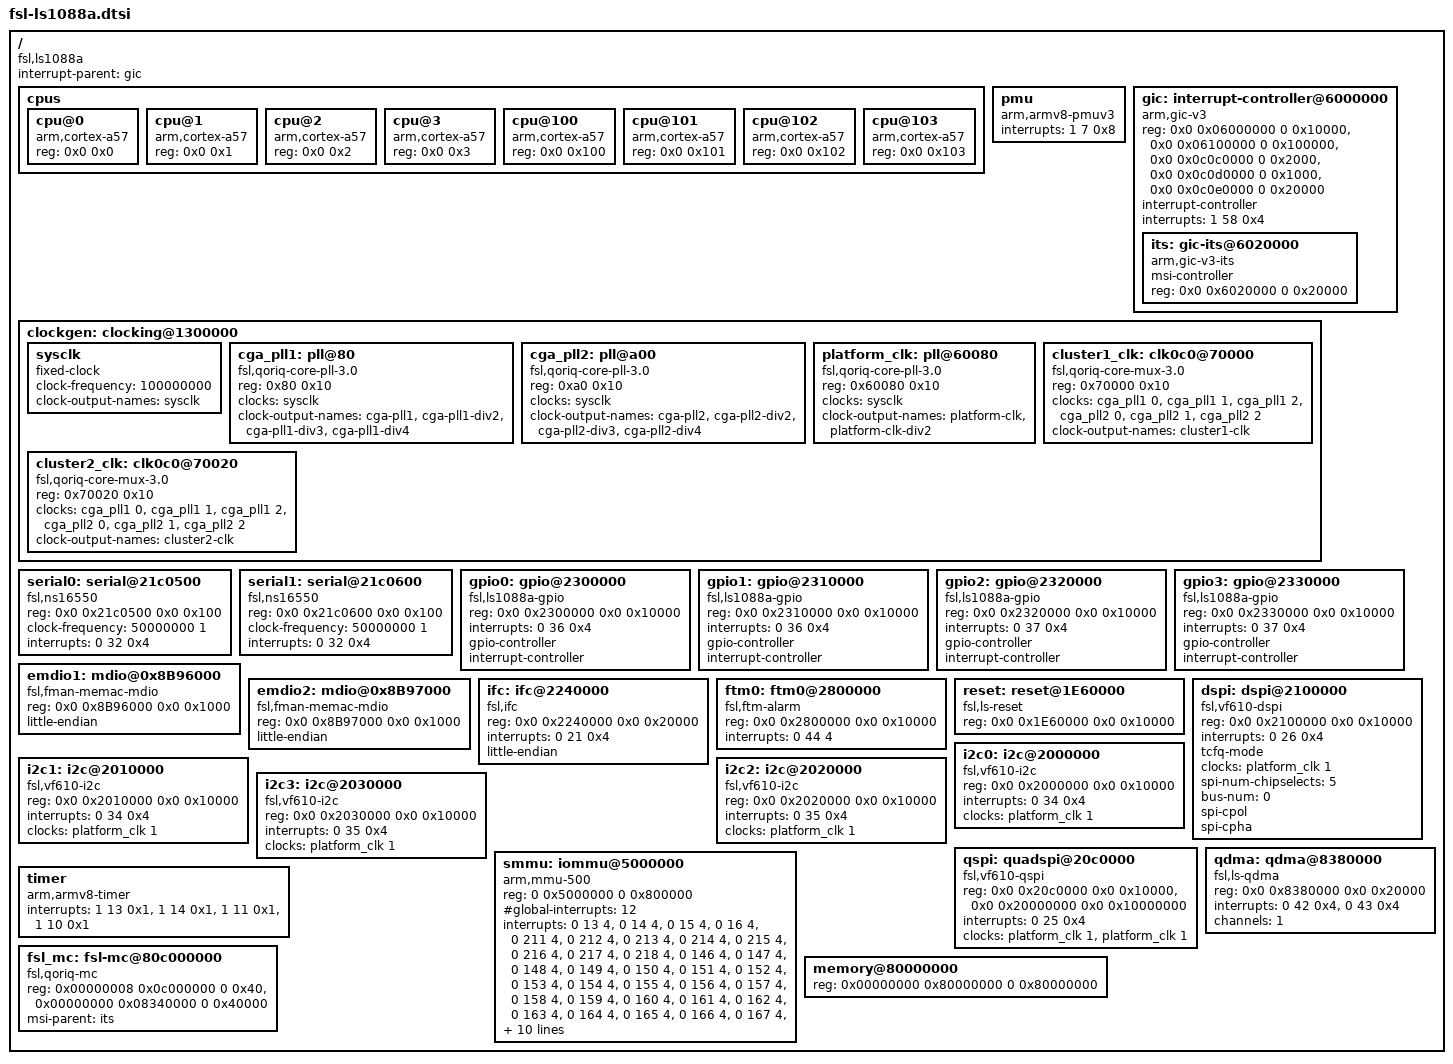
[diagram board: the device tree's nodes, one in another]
/*
 * Device Tree Include file for Freescale Layerscape-1088A family SoC.
 *
 * Copyright (C) 2015, Freescale Semiconductor
 *
 */

/memreserve/ 0x80000000 0x00010000;

/ {
	compatible = "fsl,ls1088a";
	interrupt-parent = <&gic>;
	#address-cells = <2>;
	#size-cells = <2>;

	cpus {
		#address-cells = <2>;
		#size-cells = <0>;

		/* We have 2 clusters having 4 Cortex-A57 cores each */
		cpu@0 {
			device_type = "cpu";
			compatible = "arm,cortex-a57";
			reg = <0x0 0x0>;
		};

		cpu@1 {
			device_type = "cpu";
			compatible = "arm,cortex-a57";
			reg = <0x0 0x1>;
		};

		cpu@2 {
			device_type = "cpu";
			compatible = "arm,cortex-a57";
			reg = <0x0 0x2>;
		};

		cpu@3 {
			device_type = "cpu";
			compatible = "arm,cortex-a57";
			reg = <0x0 0x3>;
		};

		cpu@100 {
			device_type = "cpu";
			compatible = "arm,cortex-a57";
			reg = <0x0 0x100>;
		};

		cpu@101 {
			device_type = "cpu";
			compatible = "arm,cortex-a57";
			reg = <0x0 0x101>;
		};

		cpu@102 {
			device_type = "cpu";
			compatible = "arm,cortex-a57";
			reg = <0x0 0x102>;
		};

		cpu@103 {
			device_type = "cpu";
			compatible = "arm,cortex-a57";
			reg = <0x0 0x103>;
		};
	};

	pmu {
		compatible = "arm,armv8-pmuv3";
		interrupts = <1 7 0x8>; /* PMU PPI, Level low type */
	};

	gic: interrupt-controller@6000000 {
		compatible = "arm,gic-v3";
		reg = <0x0 0x06000000 0 0x10000>, /* GIC Dist */
		      <0x0 0x06100000 0 0x100000>, /* GICR(RD_base+SGI_base)*/
		      <0x0 0x0c0c0000 0 0x2000>, /* GICC */
		      <0x0 0x0c0d0000 0 0x1000>, /* GICH */
		      <0x0 0x0c0e0000 0 0x20000>; /* GICV */
		#interrupt-cells = <3>;
		#address-cells = <2>;
		#size-cells = <2>;
		ranges;
		interrupt-controller;
		interrupts = <1 58 0x4>;

		its: gic-its@6020000 {
			compatible = "arm,gic-v3-its";
			msi-controller;
			reg = <0x0 0x6020000 0 0x20000>;
		};
	};

	clockgen: clocking@1300000 {
		#address-cells = <1>;
		#size-cells = <1>;
		ranges = <0x0 0x0 0x1300000 0xa0000>;

		sysclk: sysclk {
			compatible = "fixed-clock";
			#clock-cells = <0>;
			clock-frequency = <100000000>;
			clock-output-names = "sysclk";
		};

		cga_pll1: pll@80 {
			compatible = "fsl,qoriq-core-pll-3.0";
			#clock-cells = <1>;
			reg = <0x80 0x10>;
			clocks = <&sysclk>;
			clock-output-names = "cga-pll1", "cga-pll1-div2",
					     "cga-pll1-div3", "cga-pll1-div4";
		};

		cga_pll2: pll@a00 {
			compatible = "fsl,qoriq-core-pll-3.0";
			#clock-cells = <1>;
			reg = <0xa0 0x10>;
			clocks = <&sysclk>;
			clock-output-names = "cga-pll2", "cga-pll2-div2",
					     "cga-pll2-div3", "cga-pll2-div4";
		};


		platform_clk: pll@60080 {
			compatible = "fsl,qoriq-core-pll-3.0";
			#clock-cells = <1>;
			reg = <0x60080 0x10>;
			clocks = <&sysclk>;
			clock-output-names = "platform-clk",
					     "platform-clk-div2";
		};

		cluster1_clk: clk0c0@70000 {
			compatible = "fsl,qoriq-core-mux-3.0";
			#clock-cells = <0>;
			reg = <0x70000 0x10>;
			clock-names = "pll1cga", "pll1cga-div2", "pll1cga-div4",
				      "pll2cga", "pll2cga-div2", "pll2cga-div4";
			clocks = <&cga_pll1 0>, <&cga_pll1 1>, <&cga_pll1 2>,
				 <&cga_pll2 0>, <&cga_pll2 1>, <&cga_pll2 2>;
			clock-output-names = "cluster1-clk";
		};

		cluster2_clk: clk0c0@70020 {
			compatible = "fsl,qoriq-core-mux-3.0";
			#clock-cells = <0>;
			reg = <0x70020 0x10>;
			clock-names = "pll1cga", "pll1cga-div2", "pll1cga-div4",
				      "pll2cga", "pll2cga-div2", "pll2cga-div4";
			clocks = <&cga_pll1 0>, <&cga_pll1 1>, <&cga_pll1 2>,
				 <&cga_pll2 0>, <&cga_pll2 1>, <&cga_pll2 2>;
			clock-output-names = "cluster2-clk";
		};

	};

	serial0: serial@21c0500 {
		device_type = "serial";
		compatible = "fsl,ns16550", "ns16550a";
		reg = <0x0 0x21c0500 0x0 0x100>;
		clock-frequency = <50000000 1>;
		interrupts = <0 32 0x4>; /* Level high type */
	};

	serial1: serial@21c0600 {
		device_type = "serial";
		compatible = "fsl,ns16550", "ns16550a";
		reg = <0x0 0x21c0600 0x0 0x100>;
		clock-frequency = <50000000 1>;
		interrupts = <0 32 0x4>; /* Level high type */
	};

	gpio0: gpio@2300000 {
		compatible = "fsl,ls1088a-gpio";
		reg = <0x0 0x2300000 0x0 0x10000>;
		interrupts = <0 36 0x4>; /* Level high type */
		gpio-controller;
		#gpio-cells = <2>;
		interrupt-controller;
		#interrupt-cells = <2>;
	};

	gpio1: gpio@2310000 {
		compatible = "fsl,ls1088a-gpio";
		reg = <0x0 0x2310000 0x0 0x10000>;
		interrupts = <0 36 0x4>; /* Level high type */
		gpio-controller;
		#gpio-cells = <2>;
		interrupt-controller;
		#interrupt-cells = <2>;
	};

	gpio2: gpio@2320000 {
		compatible = "fsl,ls1088a-gpio";
		reg = <0x0 0x2320000 0x0 0x10000>;
		interrupts = <0 37 0x4>; /* Level high type */
		gpio-controller;
		#gpio-cells = <2>;
		interrupt-controller;
		#interrupt-cells = <2>;
	};

	gpio3: gpio@2330000 {
		compatible = "fsl,ls1088a-gpio";
		reg = <0x0 0x2330000 0x0 0x10000>;
		interrupts = <0 37 0x4>; /* Level high type */
		gpio-controller;
		#gpio-cells = <2>;
		interrupt-controller;
		#interrupt-cells = <2>;
	};

	/* TODO: WRIOP (CCSR?) */
	emdio1: mdio@0x8B96000 { /* WRIOP0: 0x8B8_0000, E-MDIO1: 0x1_6000 */
		compatible = "fsl,fman-memac-mdio";
		reg = <0x0 0x8B96000 0x0 0x1000>;
		device_type = "mdio";
		little-endian;	/* force the driver in LE mode */

		/* Not necessary on the QDS, but needed on the RDB */
		#address-cells = <1>;
		#size-cells = <0>;
	};

	emdio2: mdio@0x8B97000 { /* WRIOP0: 0x8B8_0000, E-MDIO2: 0x1_7000 */
		compatible = "fsl,fman-memac-mdio";
		reg = <0x0 0x8B97000 0x0 0x1000>;
		device_type = "mdio";
		little-endian;	/* force the driver in LE mode */

		#address-cells = <1>;
		#size-cells = <0>;
	};

	ifc: ifc@2240000 {
		compatible = "fsl,ifc", "simple-bus";
		reg = <0x0 0x2240000 0x0 0x20000>;
		interrupts = <0 21 0x4>; /* Level high type */
		little-endian;
		#address-cells = <2>;
		#size-cells = <1>;

		ranges = <0 0 0x5 0x80000000 0x08000000
			  2 0 0x5 0x30000000 0x00010000
			  3 0 0x5 0x20000000 0x00010000>;
	};



	ftm0: ftm0@2800000 {
		compatible = "fsl,ftm-alarm";
		reg = <0x0 0x2800000 0x0 0x10000>;
		interrupts = <0 44 4>;
	};

	reset: reset@1E60000 {
		compatible = "fsl,ls-reset";
		reg = <0x0 0x1E60000 0x0 0x10000>;
	};

	dspi: dspi@2100000 {
		compatible = "fsl,vf610-dspi";
		#address-cells = <1>;
		#size-cells = <0>;
		reg = <0x0 0x2100000 0x0 0x10000>;
		interrupts = <0 26 0x4>; /* Level high type */
		tcfq-mode;
		clocks = <&platform_clk 1>;
		clock-names = "dspi";
		spi-num-chipselects = <5>;
		bus-num = <0>;
		spi-cpol;
		spi-cpha;
	};

	i2c0: i2c@2000000 {
		compatible = "fsl,vf610-i2c";
		#address-cells = <1>;
		#size-cells = <0>;
		reg = <0x0 0x2000000 0x0 0x10000>;
		interrupts = <0 34 0x4>; /* Level high type */
		clock-names = "i2c";
		clocks = <&platform_clk 1>;
	};

	i2c1: i2c@2010000 {
		compatible = "fsl,vf610-i2c";
		#address-cells = <1>;
		#size-cells = <0>;
		reg = <0x0 0x2010000 0x0 0x10000>;
		interrupts = <0 34 0x4>; /* Level high type */
		clock-names = "i2c";
		clocks = <&platform_clk 1>;
	};

	i2c2: i2c@2020000 {
		compatible = "fsl,vf610-i2c";
		#address-cells = <1>;
		#size-cells = <0>;
		reg = <0x0 0x2020000 0x0 0x10000>;
		interrupts = <0 35 0x4>; /* Level high type */
		clock-names = "i2c";
		clocks = <&platform_clk 1>;
	};

	i2c3: i2c@2030000 {
		compatible = "fsl,vf610-i2c";
		#address-cells = <1>;
		#size-cells = <0>;
		reg = <0x0 0x2030000 0x0 0x10000>;
		interrupts = <0 35 0x4>; /* Level high type */
		clock-names = "i2c";
		clocks = <&platform_clk 1>;
	};

	qspi: quadspi@20c0000 {
		compatible = "fsl,vf610-qspi";
		#address-cells = <1>;
		#size-cells = <0>;
		reg = <0x0 0x20c0000 0x0 0x10000>,
		      <0x0 0x20000000 0x0 0x10000000>;
		reg-names = "QuadSPI", "QuadSPI-memory";
		interrupts = <0 25 0x4>; /* Level high type */
		clocks = <&platform_clk 1>, <&platform_clk 1>;
		clock-names = "qspi_en", "qspi";
	};

	qdma: qdma@8380000 {
		compatible = "fsl,ls-qdma";
		reg = <0x0 0x8380000 0x0 0x20000>;
		interrupts = <0 42 0x4>,
				<0 43 0x4>;
		interrupt-names = "qdma-tx", "qdma-err";
		channels = <1>;
	};




	smmu: iommu@5000000 {
		compatible = "arm,mmu-500";
		reg = <0 0x5000000 0 0x800000>;
		#global-interrupts = <12>;
		interrupts = <0 13 4>, /* global secure fault */
			     <0 14 4>, /* combined secure interrupt */
			     <0 15 4>, /* global non-secure fault */
			     <0 16 4>, /* combined non-secure interrupt */
			/* performance counter interrupts 0-7 */
			     <0 211 4>,
			     <0 212 4>,
			     <0 213 4>,
			     <0 214 4>,
			     <0 215 4>,
			     <0 216 4>,
			     <0 217 4>,
			     <0 218 4>,
			/* per context interrupt, 64 interrupts */
			     <0 146 4>,
			     <0 147 4>,
			     <0 148 4>,
			     <0 149 4>,
			     <0 150 4>,
			     <0 151 4>,
			     <0 152 4>,
			     <0 153 4>,
			     <0 154 4>,
			     <0 155 4>,
			     <0 156 4>,
			     <0 157 4>,
			     <0 158 4>,
			     <0 159 4>,
			     <0 160 4>,
			     <0 161 4>,
			     <0 162 4>,
			     <0 163 4>,
			     <0 164 4>,
			     <0 165 4>,
			     <0 166 4>,
			     <0 167 4>,
			     <0 168 4>,
			     <0 169 4>,
			     <0 170 4>,
			     <0 171 4>,
			     <0 172 4>,
			     <0 173 4>,
			     <0 174 4>,
			     <0 175 4>,
			     <0 176 4>,
			     <0 177 4>,
			     <0 178 4>,
			     <0 179 4>,
			     <0 180 4>,
			     <0 181 4>,
			     <0 182 4>,
			     <0 183 4>,
			     <0 184 4>,
			     <0 185 4>,
			     <0 186 4>,
			     <0 187 4>,
			     <0 188 4>,
			     <0 189 4>,
			     <0 190 4>,
			     <0 191 4>,
			     <0 192 4>,
			     <0 193 4>,
			     <0 194 4>,
			     <0 195 4>,
			     <0 196 4>,
			     <0 197 4>,
			     <0 198 4>,
			     <0 199 4>,
			     <0 200 4>,
			     <0 201 4>,
			     <0 202 4>,
			     <0 203 4>,
			     <0 204 4>,
			     <0 205 4>,
			     <0 206 4>,
			     <0 207 4>,
			     <0 208 4>,
			     <0 209 4>;
		mmu-masters = <&fsl_mc 0x300 0>;
	};

	timer {
		compatible = "arm,armv8-timer";
		interrupts = <1 13 0x1>,/*Phy Secure PPI, edge triggered*/
			     <1 14 0x1>, /*Phy Non-Secure PPI, edge triggered*/
			     <1 11 0x1>, /*Virtual PPI, edge triggered */
			     <1 10 0x1>; /*Hypervisor PPI, edge triggered */
	};

	fsl_mc: fsl-mc@80c000000 {
		compatible = "fsl,qoriq-mc";
		#stream-id-cells = <2>;
		reg = <0x00000008 0x0c000000 0 0x40>,	 /* MC portal base */
		      <0x00000000 0x08340000 0 0x40000>; /* MC control reg */
		msi-parent = <&its>;
		#address-cells = <3>;
		#size-cells = <1>;

		/*
		 * Region type 0x0 - MC portals
		 * Region type 0x1 - QBMAN portals
		 */
		ranges = <0x0 0x0 0x0 0x8 0x0c000000 0x4000000
			  0x1 0x0 0x0 0x8 0x18000000 0x8000000>;
	};

/*	ccn@4000000 {
		compatible = "arm,ccn-504";
		reg = <0x0 0x04000000 0x0 0x01000000>;
		interrupts = <0 12 4>;
	};*/

	memory@80000000 {
		device_type = "memory";
		reg = <0x00000000 0x80000000 0 0x80000000>;
		      /* DRAM space 1 - 2 GB DRAM */
	};
};
